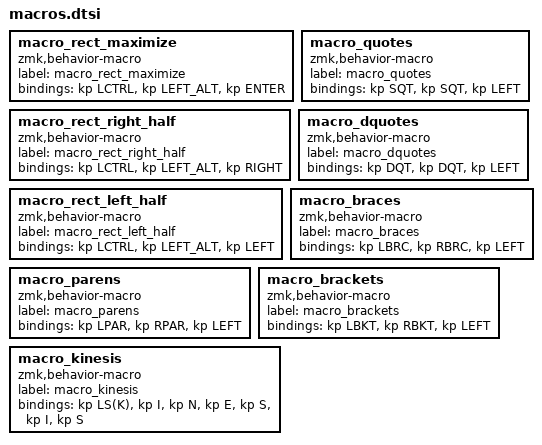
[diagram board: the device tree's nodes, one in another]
macro_rect_maximize: macro_rect_maximize{
compatible = "zmk,behavior-macro";
label = "macro_rect_maximize";
#binding-cells = <0>;
bindings = <&kp LCTRL>, <&kp LEFT_ALT>, <&kp ENTER>;
};
macro_rect_right_half: macro_rect_right_half{
compatible = "zmk,behavior-macro";
label = "macro_rect_right_half";
#binding-cells = <0>;
bindings = <&kp LCTRL>, <&kp LEFT_ALT>, <&kp RIGHT>;
};
macro_rect_left_half: macro_rect_left_half{
compatible = "zmk,behavior-macro";
label = "macro_rect_left_half";
#binding-cells = <0>;
bindings = <&kp LCTRL>, <&kp LEFT_ALT>, <&kp LEFT>;
};
macro_quotes: macro_quotes{
compatible = "zmk,behavior-macro";
label = "macro_quotes";
#binding-cells = <0>;
bindings = <&kp SQT>, <&kp SQT>, <&kp LEFT>;
};
macro_dquotes: macro_dquotes{
compatible = "zmk,behavior-macro";
label = "macro_dquotes";
#binding-cells = <0>;
bindings = <&kp DQT>, <&kp DQT>, <&kp LEFT>;
};
macro_braces: macro_braces{
compatible = "zmk,behavior-macro";
label = "macro_braces";
#binding-cells = <0>;
bindings = <&kp LBRC>, <&kp RBRC>, <&kp LEFT>;
};
macro_parens: macro_parens{
compatible = "zmk,behavior-macro";
label = "macro_parens";
#binding-cells = <0>;
bindings = <&kp LPAR>, <&kp RPAR>, <&kp LEFT>;
};
macro_brackets: macro_brackets{
compatible = "zmk,behavior-macro";
label = "macro_brackets";
#binding-cells = <0>;
bindings = <&kp LBKT>, <&kp RBKT>, <&kp LEFT>;
};
macro_kinesis: macro_kinesis{
compatible = "zmk,behavior-macro";
label = "macro_kinesis";
#binding-cells = <0>;
bindings = <&kp LS(K)>, <&kp I>, <&kp N>, <&kp E>, <&kp S>, <&kp I>, <&kp S>;
};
